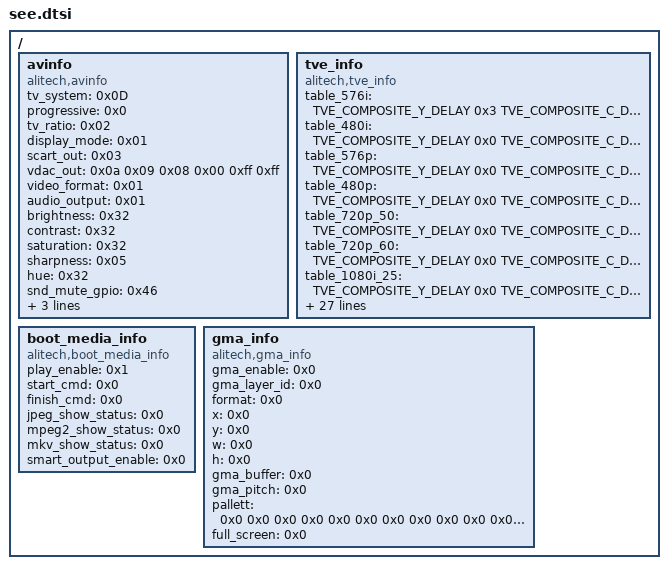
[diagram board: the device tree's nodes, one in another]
/*
 * ALi platform DTS
 * Copyright(C) 2014 ALi Corporation. All rights reserved.
 *
 * This program is free software; you can redistribute it and/or modify
 * it under the terms of the GNU General Public License version 2 as
 * published by the Free Software Foundation.
 *
 * This program is distributed in the hope that it will be useful,
 * but WITHOUT ANY WARRANTY; without even the implied warranty of
 * MERCHANTABILITY or FITNESS FOR A PARTICULAR PURPOSE.  See the
 * GNU General Public License for more details.
 */
 
#include "tve.h"

/{
		#size-cells = <2>;
		avinfo{
			compatible="alitech,avinfo";
			/*eric.cai debug*/
			/* tv_system = /bits/ 8 <0x0D>; */
			tv_system = /bits/ 8 <0x0D>; 
			progressive = /bits/ 8 <0x0>;
			tv_ratio= /bits/ 8 <0x02>;
			display_mode = /bits/ 8 <0x01>;
			scart_out = /bits/ 8 <0x03>;
			vdac_out = /bits/ 8 <0x0a 0x09 0x08 0x00 0xff 0xff>;
			video_format = /bits/ 8 <0x01>;
			audio_output = /bits/ 8 <0x01>;
			brightness = /bits/ 8 <0x32>;
			contrast = /bits/ 8 <0x32>;
			saturation = /bits/ 8 <0x32>;
			sharpness = /bits/ 8 <0x05>;
			hue = /bits/ 8 <0x32>;
			snd_mute_gpio = /bits/ 8 <0x46>;
			snd_mute_polar = /bits/ 8 <0x0>;
			hdcp_disable = /bits/ 8 <0x01>;
			resv = /bits/ 8 <0x00 0x01 0x02 0x03 0x04 0x05 0x06>;
		};
		tve_info{ 
		compatible="alitech,tve_info";
		table_576i = 
	  	< /* field_index  field_value */
			 
				 TVE_COMPOSITE_Y_DELAY              0x3  
				 TVE_COMPOSITE_C_DELAY              0x6  
				 TVE_COMPOSITE_LUMA_LEVEL           0x51  
				 TVE_COMPOSITE_CHRMA_LEVEL          0x67  
				 TVE_COMPOSITE_SYNC_DELAY           0x3  
				 TVE_COMPOSITE_SYNC_LEVEL           0x2  
				 TVE_COMPOSITE_FILTER_C_ENALBE      0x0  
				 TVE_COMPOSITE_FILTER_Y_ENALBE      0x1  
				 TVE_COMPOSITE_PEDESTAL_LEVEL       0x0  
			
				 TVE_COMPONENT_IS_PAL               0x1  
				 TVE_COMPONENT_PAL_MODE             0x0  
				 TVE_COMPONENT_ALL_SMOOTH_ENABLE    0x0  
				 TVE_COMPONENT_BTB_ENALBE           0x0  
				 TVE_COMPONENT_INSERT0_ONOFF        0x1  
				 TVE_COMPONENT_DAC_UPSAMPLEN        0x1  
				 TVE_COMPONENT_Y_DELAY              0x2  
				 TVE_COMPONENT_CB_DELAY             0x2  
				 TVE_COMPONENT_CR_DELAY             0x2  
				 TVE_COMPONENT_LUM_LEVEL            0x52  
				 TVE_COMPONENT_CHRMA_LEVEL          0x50  
				 TVE_COMPONENT_PEDESTAL_LEVEL       0xb  
				 TVE_COMPONENT_UV_SYNC_ONOFF        0x0  
				 TVE_COMPONENT_SYNC_DELAY           0x7  
				 TVE_COMPONENT_SYNC_LEVEL           0x3  
				 TVE_COMPONENT_R_SYNC_ONOFF         0x0  
				 TVE_COMPONENT_G_SYNC_ONOFF         0x0  
				 TVE_COMPONENT_B_SYNC_ONOFF         0x0  
				 TVE_COMPONENT_RGB_R_LEVEL          0x47  
				 TVE_COMPONENT_RGB_G_LEVEL          0x47  
				 TVE_COMPONENT_RGB_B_LEVEL          0x47  
				 TVE_COMPONENT_FILTER_Y_ENALBE      0x1  
				 TVE_COMPONENT_FILTER_C_ENALBE      0x1  
				 TVE_COMPONENT_PEDESTAL_ONOFF       0x0  
				 TVE_COMPONENT_PED_RGB_YPBPR_ENABLE 0x0  
				 TVE_COMPONENT_PED_ADJUST           0x0  
				 TVE_COMPONENT_G2Y                  0x12a  
				 TVE_COMPONENT_G2U                  0x64  
				 TVE_COMPONENT_G2V                  0xd0  
				 TVE_COMPONENT_B2U                  0x205  
				 TVE_COMPONENT_R2V                  0x198  
			
			
				 TVE_BURST_POS_ENABLE               0x1  
				 TVE_BURST_LEVEL_ENABLE             0x1  
				 TVE_BURST_CB_LEVEL                 0x96  
				 TVE_BURST_CR_LEVEL                 0x6a  
				 TVE_BURST_START_POS                0x55  
				 TVE_BURST_END_POS                  0x74  
				 TVE_BURST_SET_FREQ_MODE            0x0  
				 TVE_BURST_FREQ_SIGN                0x0  
				 TVE_BURST_PHASE_COMPENSATION       0x61e8  
				 TVE_BURST_FREQ_RESPONSE            0x0  
			
			
				 TVE_ASYNC_FIFO                     0x4  
				 TVE_CAV_SYNC_HIGH                  0x1  
				 TVE_SYNC_HIGH_WIDTH                0x6  
				 TVE_SYNC_LOW_WIDTH                 0xd  
			
			
				 TVE_VIDEO_DAC_FS                   0x0  
				 TVE_SECAM_PRE_COEFFA3A2            0x0  
				 TVE_SECAM_PRE_COEFFB1A4            0x0  
				 TVE_SECAM_PRE_COEFFB3B2            0x0  
				 TVE_SECAM_F0CB_CENTER              0x0  
				 TVE_SECAM_F0CR_CENTER              0x0  
				 TVE_SECAM_FM_KCBCR_AJUST           0x0  
				 TVE_SECAM_CONTROL                  0x0  
				 TVE_SECAM_NOTCH_COEFB1             0x0  
				 TVE_SECAM_NOTCH_COEFB2B3           0x0  
				 TVE_SECAM_NOTCH_COEFA2A3           0x0  
			
			   //added
			   TVE_COMPONENT_PLUG_OUT_EN          0x1  
				 TVE_COMPONENT_PLUG_DETECT_LINE_CNT_HD 0x4  
				 TVE_CB_CR_INSERT_SW                0x0  //0x84 28bit
				 TVE_VBI_LINE21_EN                  0x0  //0xc8 14bit
			   TVE_COMPONENT_PLUG_DETECT_AMP_ADJUST_HD    0x60  
				 TVE_SCART_PLUG_DETECT_LINE_CNT_HD  0x0        
				 TVE_SCART_PLUG_DETECT_AMP_ADJUST_HD 0x0       
			   TVE_COMPONENT_PLUG_DETECT_FRAME_COUNT 0x1F  
			   TVE_COMPONENT_PLUG_DETECT_VCOUNT 0x2  
			   TVE_COMPONENT_VDAC_ENBUF 0x0  
		>;
		table_480i = 
		< /* field_index  field_value */
		  
				 TVE_COMPOSITE_Y_DELAY              0x0  
				 TVE_COMPOSITE_C_DELAY              0x3  
				 TVE_COMPOSITE_LUMA_LEVEL           0x4c  
				 TVE_COMPOSITE_CHRMA_LEVEL          0x60  
				 TVE_COMPOSITE_SYNC_DELAY           0x0  
				 TVE_COMPOSITE_SYNC_LEVEL           0x5  
				 TVE_COMPOSITE_FILTER_C_ENALBE      0x0  
				 TVE_COMPOSITE_FILTER_Y_ENALBE      0x1  
				 TVE_COMPOSITE_PEDESTAL_LEVEL       0x0  
			
			
				 TVE_COMPONENT_IS_PAL               0x0  
				 TVE_COMPONENT_PAL_MODE             0x0  
				 TVE_COMPONENT_ALL_SMOOTH_ENABLE    0x0  
				 TVE_COMPONENT_BTB_ENALBE           0x1  
				 TVE_COMPONENT_INSERT0_ONOFF        0x1  
				 TVE_COMPONENT_DAC_UPSAMPLEN        0x1  
				 TVE_COMPONENT_Y_DELAY              0x3  
				 TVE_COMPONENT_CB_DELAY             0x1  
				 TVE_COMPONENT_CR_DELAY             0x1  
				 TVE_COMPONENT_LUM_LEVEL            0x4c  
				 TVE_COMPONENT_CHRMA_LEVEL          0x52  
				 TVE_COMPONENT_PEDESTAL_LEVEL       0xb  
				 TVE_COMPONENT_UV_SYNC_ONOFF        0x0  
				 TVE_COMPONENT_SYNC_DELAY           0x7  
				 TVE_COMPONENT_SYNC_LEVEL           0x3  
				 TVE_COMPONENT_R_SYNC_ONOFF         0x0  
				 TVE_COMPONENT_G_SYNC_ONOFF         0x0  
				 TVE_COMPONENT_B_SYNC_ONOFF         0x0  
				 TVE_COMPONENT_RGB_R_LEVEL          0x47  
				 TVE_COMPONENT_RGB_G_LEVEL          0x47  
				 TVE_COMPONENT_RGB_B_LEVEL          0x47  
				 TVE_COMPONENT_FILTER_Y_ENALBE      0x1  
				 TVE_COMPONENT_FILTER_C_ENALBE      0x1  
				 TVE_COMPONENT_PEDESTAL_ONOFF       0x1  
				 TVE_COMPONENT_PED_RGB_YPBPR_ENABLE 0x1  
				 TVE_COMPONENT_PED_ADJUST           0xa8  
				 TVE_COMPONENT_G2Y                  0x12a  
				 TVE_COMPONENT_G2U                  0x64  
				 TVE_COMPONENT_G2V                  0xd0  
				 TVE_COMPONENT_B2U                  0x205  
				 TVE_COMPONENT_R2V                  0x198  
			
			
				 TVE_BURST_POS_ENABLE               0x0  
				 TVE_BURST_LEVEL_ENABLE             0x1  
				 TVE_BURST_CB_LEVEL                 0xd4  
				 TVE_BURST_CR_LEVEL                 0x0  
				 TVE_BURST_START_POS                0x55  
				 TVE_BURST_END_POS                  0x74  
				 TVE_BURST_SET_FREQ_MODE            0x0  
				 TVE_BURST_FREQ_SIGN                0x0  
				 TVE_BURST_PHASE_COMPENSATION       0x3400  
				 TVE_BURST_FREQ_RESPONSE            0x0  
			
			
				 TVE_ASYNC_FIFO                     0x4  
				 TVE_CAV_SYNC_HIGH                  0x1  
				 TVE_SYNC_HIGH_WIDTH                0x6  
				 TVE_SYNC_LOW_WIDTH                 0xd  
			
			
				 TVE_VIDEO_DAC_FS                   0x0  
				 TVE_SECAM_PRE_COEFFA3A2            0x0  
				 TVE_SECAM_PRE_COEFFB1A4            0x0  
				 TVE_SECAM_PRE_COEFFB3B2            0x0  
				 TVE_SECAM_F0CB_CENTER              0x0  
				 TVE_SECAM_F0CR_CENTER              0x0  
				 TVE_SECAM_FM_KCBCR_AJUST           0x0  
				 TVE_SECAM_CONTROL                  0x0  
				 TVE_SECAM_NOTCH_COEFB1             0x0  
				 TVE_SECAM_NOTCH_COEFB2B3           0x0  
				 TVE_SECAM_NOTCH_COEFA2A3           0x0  
				 //added
			   TVE_COMPONENT_PLUG_OUT_EN          0x1  
				 TVE_COMPONENT_PLUG_DETECT_LINE_CNT_HD 0x7  
				 TVE_CB_CR_INSERT_SW                0x1  //0x84 28bit	//C3511 éè3é1￡?S3511 éè3é0
				 TVE_VBI_LINE21_EN                  0x1  //0xc8 14bit
			   TVE_COMPONENT_PLUG_DETECT_AMP_ADJUST_HD                  0x60  
				 TVE_SCART_PLUG_DETECT_LINE_CNT_HD  0x0        
				 TVE_SCART_PLUG_DETECT_AMP_ADJUST_HD 0x0       
			   TVE_COMPONENT_PLUG_DETECT_FRAME_COUNT 0x1F  
			   TVE_COMPONENT_PLUG_DETECT_VCOUNT 0x2  
			   TVE_COMPONENT_VDAC_ENBUF 0x0  

		>;
		table_576p = 
		< /* field_index  field_value */
	 
				 TVE_COMPOSITE_Y_DELAY              0x0  
				 TVE_COMPOSITE_C_DELAY              0x2  
				 TVE_COMPOSITE_LUMA_LEVEL           0x50  
				 TVE_COMPOSITE_CHRMA_LEVEL          0x68  
				 TVE_COMPOSITE_SYNC_DELAY           0x0  
				 TVE_COMPOSITE_SYNC_LEVEL           0x4  
				 TVE_COMPOSITE_FILTER_C_ENALBE      0x0  
				 TVE_COMPOSITE_FILTER_Y_ENALBE      0x1  
				 TVE_COMPOSITE_PEDESTAL_LEVEL       0x0  

				 TVE_COMPONENT_IS_PAL               0x0  
				 TVE_COMPONENT_PAL_MODE             0x0  
				 TVE_COMPONENT_ALL_SMOOTH_ENABLE    0x0  
				 TVE_COMPONENT_BTB_ENALBE           0x0  
				 TVE_COMPONENT_INSERT0_ONOFF        0x1  
				 TVE_COMPONENT_DAC_UPSAMPLEN        0x1  
				 TVE_COMPONENT_Y_DELAY              0x1  
				 TVE_COMPONENT_CB_DELAY             0x1  
				 TVE_COMPONENT_CR_DELAY             0x1  
				 TVE_COMPONENT_LUM_LEVEL            0x52  
				 TVE_COMPONENT_CHRMA_LEVEL          0x52  
				 TVE_COMPONENT_PEDESTAL_LEVEL       0xa  
				 TVE_COMPONENT_UV_SYNC_ONOFF        0x0  
				 TVE_COMPONENT_SYNC_DELAY           0x7  
				 TVE_COMPONENT_SYNC_LEVEL           0x3  
				 TVE_COMPONENT_R_SYNC_ONOFF         0x0  
				 TVE_COMPONENT_G_SYNC_ONOFF         0x0  
				 TVE_COMPONENT_B_SYNC_ONOFF         0x0  
				 TVE_COMPONENT_RGB_R_LEVEL          0x49  
				 TVE_COMPONENT_RGB_G_LEVEL          0x49  
				 TVE_COMPONENT_RGB_B_LEVEL          0x49  
				 TVE_COMPONENT_FILTER_Y_ENALBE      0x1  
				 TVE_COMPONENT_FILTER_C_ENALBE      0x1  
				 TVE_COMPONENT_PEDESTAL_ONOFF       0x0  
				 TVE_COMPONENT_PED_RGB_YPBPR_ENABLE 0x0  
				 TVE_COMPONENT_PED_ADJUST           0x0  
				 TVE_COMPONENT_G2Y                  0x12a  
				 TVE_COMPONENT_G2U                  0x64  
				 TVE_COMPONENT_G2V                  0xd0  
				 TVE_COMPONENT_B2U                  0x205  
				 TVE_COMPONENT_R2V                  0x198  

				 TVE_BURST_POS_ENABLE               0x0  
				 TVE_BURST_LEVEL_ENABLE             0x0  
				 TVE_BURST_CB_LEVEL                 0xd4  
				 TVE_BURST_CR_LEVEL                 0x0  
				 TVE_BURST_START_POS                0x0  
				 TVE_BURST_END_POS                  0x0  
				 TVE_BURST_SET_FREQ_MODE            0x0  
				 TVE_BURST_FREQ_SIGN                0x0  
				 TVE_BURST_PHASE_COMPENSATION       0x0  
				 TVE_BURST_FREQ_RESPONSE            0x0  

				 TVE_ASYNC_FIFO                     0x4  
				 TVE_CAV_SYNC_HIGH                  0x1  
				 TVE_SYNC_HIGH_WIDTH                0x6  
				 TVE_SYNC_LOW_WIDTH                 0xd  

				 TVE_VIDEO_DAC_FS                   0x0  
				 TVE_SECAM_PRE_COEFFA3A2            0x0  
				 TVE_SECAM_PRE_COEFFB1A4            0x0  
				 TVE_SECAM_PRE_COEFFB3B2            0x0  
				 TVE_SECAM_F0CB_CENTER              0x0  
				 TVE_SECAM_F0CR_CENTER              0x0  
				 TVE_SECAM_FM_KCBCR_AJUST           0x0  
				 TVE_SECAM_CONTROL                  0x0  
				 TVE_SECAM_NOTCH_COEFB1             0x0  
				 TVE_SECAM_NOTCH_COEFB2B3           0x0  
				 TVE_SECAM_NOTCH_COEFA2A3           0x0  
				 TVE_COMPONENT_PLUG_OUT_EN          0x1        
				 TVE_COMPONENT_PLUG_DETECT_LINE_CNT_HD 0xe     
				 TVE_CB_CR_INSERT_SW                0x0        
				 TVE_VBI_LINE21_EN                  0x0        
				 TVE_COMPONENT_PLUG_DETECT_AMP_ADJUST_HD 0x60  
				 TVE_SCART_PLUG_DETECT_LINE_CNT_HD  0x0        
				 TVE_SCART_PLUG_DETECT_AMP_ADJUST_HD 0x0       
				 TVE_COMPONENT_PLUG_DETECT_FRAME_COUNT 0x1F     
				 TVE_COMPONENT_PLUG_DETECT_VCOUNT 0x2          
				 TVE_COMPONENT_VDAC_ENBUF 0x0                  
   >;
	 table_480p = 
	 </* field_index  field_value */ 
				  
				 TVE_COMPOSITE_Y_DELAY              0x0  
				 TVE_COMPOSITE_C_DELAY              0x2  
				 TVE_COMPOSITE_LUMA_LEVEL           0x50  
				 TVE_COMPOSITE_CHRMA_LEVEL          0x68  
				 TVE_COMPOSITE_SYNC_DELAY           0x0  
				 TVE_COMPOSITE_SYNC_LEVEL           0x4  
				 TVE_COMPOSITE_FILTER_C_ENALBE      0x0  
				 TVE_COMPOSITE_FILTER_Y_ENALBE      0x1  
				 TVE_COMPOSITE_PEDESTAL_LEVEL       0x0  
			
			
				 TVE_COMPONENT_IS_PAL               0x0  
				 TVE_COMPONENT_PAL_MODE             0x0  
				 TVE_COMPONENT_ALL_SMOOTH_ENABLE    0x0  
				 TVE_COMPONENT_BTB_ENALBE           0x0  
				 TVE_COMPONENT_INSERT0_ONOFF        0x1  
				 TVE_COMPONENT_DAC_UPSAMPLEN        0x1  
				 TVE_COMPONENT_Y_DELAY              0x1  
				 TVE_COMPONENT_CB_DELAY             0x1  
				 TVE_COMPONENT_CR_DELAY             0x1  
				 TVE_COMPONENT_LUM_LEVEL            0x52  
				 TVE_COMPONENT_CHRMA_LEVEL          0x52  
				 TVE_COMPONENT_PEDESTAL_LEVEL       0xa  
				 TVE_COMPONENT_UV_SYNC_ONOFF        0x0  
				 TVE_COMPONENT_SYNC_DELAY           0x7  
				 TVE_COMPONENT_SYNC_LEVEL           0x3  
				 TVE_COMPONENT_R_SYNC_ONOFF         0x0  
				 TVE_COMPONENT_G_SYNC_ONOFF         0x0  
				 TVE_COMPONENT_B_SYNC_ONOFF         0x0  
				 TVE_COMPONENT_RGB_R_LEVEL          0x49  
				 TVE_COMPONENT_RGB_G_LEVEL          0x49  
				 TVE_COMPONENT_RGB_B_LEVEL          0x49  
				 TVE_COMPONENT_FILTER_Y_ENALBE      0x1  
				 TVE_COMPONENT_FILTER_C_ENALBE      0x1  
				 TVE_COMPONENT_PEDESTAL_ONOFF       0x0  
				 TVE_COMPONENT_PED_RGB_YPBPR_ENABLE 0x0  
				 TVE_COMPONENT_PED_ADJUST           0x0  
				 TVE_COMPONENT_G2Y                  0x12a  
				 TVE_COMPONENT_G2U                  0x64  
				 TVE_COMPONENT_G2V                  0xd0  
				 TVE_COMPONENT_B2U                  0x205  
				 TVE_COMPONENT_R2V                  0x198  
			
			
				 TVE_BURST_POS_ENABLE               0x0  
				 TVE_BURST_LEVEL_ENABLE             0x0  
				 TVE_BURST_CB_LEVEL                 0xd4  
				 TVE_BURST_CR_LEVEL                 0x0  
				 TVE_BURST_START_POS                0x0  
				 TVE_BURST_END_POS                  0x0  
				 TVE_BURST_SET_FREQ_MODE            0x0  
				 TVE_BURST_FREQ_SIGN                0x0  
				 TVE_BURST_PHASE_COMPENSATION       0x0  
				 TVE_BURST_FREQ_RESPONSE            0x0  
			
			
				 TVE_ASYNC_FIFO                     0x4  
				 TVE_CAV_SYNC_HIGH                  0x1  
				 TVE_SYNC_HIGH_WIDTH                0x6  
				 TVE_SYNC_LOW_WIDTH                 0xd  
			
			
				 TVE_VIDEO_DAC_FS                   0x0  
				 TVE_SECAM_PRE_COEFFA3A2            0x0  
				 TVE_SECAM_PRE_COEFFB1A4            0x0  
				 TVE_SECAM_PRE_COEFFB3B2            0x0  
				 TVE_SECAM_F0CB_CENTER              0x0  
				 TVE_SECAM_F0CR_CENTER              0x0  
				 TVE_SECAM_FM_KCBCR_AJUST           0x0  
				 TVE_SECAM_CONTROL                  0x0  
				 TVE_SECAM_NOTCH_COEFB1             0x0  
				 TVE_SECAM_NOTCH_COEFB2B3           0x0  
				 TVE_SECAM_NOTCH_COEFA2A3           0x0  
			   //added
			   TVE_COMPONENT_PLUG_OUT_EN          0x1  
				 TVE_COMPONENT_PLUG_DETECT_LINE_CNT_HD 0xe     
				 TVE_CB_CR_INSERT_SW                0x0  //0x84 28bit
				 TVE_VBI_LINE21_EN                  0x0  //0xc8 14bit
			   TVE_COMPONENT_PLUG_DETECT_AMP_ADJUST_HD    0x60  
			   TVE_SCART_PLUG_DETECT_LINE_CNT_HD  0x0  
				 TVE_SCART_PLUG_DETECT_AMP_ADJUST_HD 0x0       

			   TVE_COMPONENT_PLUG_DETECT_FRAME_COUNT 0x1F  
			   TVE_COMPONENT_PLUG_DETECT_VCOUNT 0x2  
			   TVE_COMPONENT_VDAC_ENBUF 0x0  
			>;
			table_720p_50 = 
			</* field_index  field_value */
				  
			 TVE_COMPOSITE_Y_DELAY              0x0  
			 TVE_COMPOSITE_C_DELAY              0x2  
			 TVE_COMPOSITE_LUMA_LEVEL           0x50  
			 TVE_COMPOSITE_CHRMA_LEVEL          0x68  
			 TVE_COMPOSITE_SYNC_DELAY           0x0  
			 TVE_COMPOSITE_SYNC_LEVEL           0x4  
			 TVE_COMPOSITE_FILTER_C_ENALBE      0x0  
			 TVE_COMPOSITE_FILTER_Y_ENALBE      0x1  
			 TVE_COMPOSITE_PEDESTAL_LEVEL       0x0  

			 TVE_COMPONENT_IS_PAL               0x0  
			 TVE_COMPONENT_PAL_MODE             0x0  
			 TVE_COMPONENT_ALL_SMOOTH_ENABLE    0x0  
			 TVE_COMPONENT_BTB_ENALBE           0x0  
			 TVE_COMPONENT_INSERT0_ONOFF        0x1  
			 TVE_COMPONENT_DAC_UPSAMPLEN        0x1  
			 TVE_COMPONENT_Y_DELAY              0x6  
			 TVE_COMPONENT_CB_DELAY             0x5  
			 TVE_COMPONENT_CR_DELAY             0x5  
			 TVE_COMPONENT_LUM_LEVEL            0x52  
			 TVE_COMPONENT_CHRMA_LEVEL          0x52  
			 TVE_COMPONENT_PEDESTAL_LEVEL       0x0  
			 TVE_COMPONENT_UV_SYNC_ONOFF        0x0  
			 TVE_COMPONENT_SYNC_DELAY           0x0  
			 TVE_COMPONENT_SYNC_LEVEL           0x3  
			 TVE_COMPONENT_R_SYNC_ONOFF         0x0  
			 TVE_COMPONENT_G_SYNC_ONOFF         0x0  
			 TVE_COMPONENT_B_SYNC_ONOFF         0x0  
			 TVE_COMPONENT_RGB_R_LEVEL          0x49  
			 TVE_COMPONENT_RGB_G_LEVEL          0x49  
			 TVE_COMPONENT_RGB_B_LEVEL          0x49  
			 TVE_COMPONENT_FILTER_Y_ENALBE      0x1  
			 TVE_COMPONENT_FILTER_C_ENALBE      0x1  
			 TVE_COMPONENT_PEDESTAL_ONOFF       0x0  
			 TVE_COMPONENT_PED_RGB_YPBPR_ENABLE 0x0  
			 TVE_COMPONENT_PED_ADJUST           0x0  
			 TVE_COMPONENT_G2Y                  0x12a  
			 TVE_COMPONENT_G2U                  0x64  
			 TVE_COMPONENT_G2V                  0xd0  
			 TVE_COMPONENT_B2U                  0x21d  
			 TVE_COMPONENT_R2V                  0x1cb  

			 TVE_BURST_POS_ENABLE               0x0  
			 TVE_BURST_LEVEL_ENABLE             0x0  
			 TVE_BURST_CB_LEVEL                 0xd4  
			 TVE_BURST_CR_LEVEL                 0x0  
			 TVE_BURST_START_POS                0x0  
			 TVE_BURST_END_POS                  0x0  
			 TVE_BURST_SET_FREQ_MODE            0x0  
			 TVE_BURST_FREQ_SIGN                0x0  
			 TVE_BURST_PHASE_COMPENSATION       0x0  
			 TVE_BURST_FREQ_RESPONSE            0x0  

			 TVE_ASYNC_FIFO                     0x4  
			 TVE_CAV_SYNC_HIGH                  0x1  
			 TVE_SYNC_HIGH_WIDTH                0x6  
			 TVE_SYNC_LOW_WIDTH                 0xd  

			 TVE_VIDEO_DAC_FS                   0x0  
			 TVE_SECAM_PRE_COEFFA3A2            0x0  
			 TVE_SECAM_PRE_COEFFB1A4            0x0  
			 TVE_SECAM_PRE_COEFFB3B2            0x0  
			 TVE_SECAM_F0CB_CENTER              0x0  
			 TVE_SECAM_F0CR_CENTER              0x0  
			 TVE_SECAM_FM_KCBCR_AJUST           0x0  
			 TVE_SECAM_CONTROL                  0x0  
			 TVE_SECAM_NOTCH_COEFB1             0x0  
			 TVE_SECAM_NOTCH_COEFB2B3           0x0  
			 TVE_SECAM_NOTCH_COEFA2A3           0x0  
			 TVE_COMPONENT_PLUG_OUT_EN          0x1        
			 TVE_COMPONENT_PLUG_DETECT_LINE_CNT_HD 0x6     
			 TVE_CB_CR_INSERT_SW                0x0        
			 TVE_VBI_LINE21_EN                  0x0        
			 TVE_COMPONENT_PLUG_DETECT_AMP_ADJUST_HD 0x60  
			 TVE_SCART_PLUG_DETECT_LINE_CNT_HD  0x0        
			 TVE_SCART_PLUG_DETECT_AMP_ADJUST_HD 0x0       
			 TVE_COMPONENT_PLUG_DETECT_FRAME_COUNT 0x1F     
			 TVE_COMPONENT_PLUG_DETECT_VCOUNT 0x2          
			 TVE_COMPONENT_VDAC_ENBUF 0x0                  

				>;
		table_720p_60 = 
		</* field_index  field_value */					 
			 
			 TVE_COMPOSITE_Y_DELAY              0x0  
			 TVE_COMPOSITE_C_DELAY              0x2  
			 TVE_COMPOSITE_LUMA_LEVEL           0x50  
			 TVE_COMPOSITE_CHRMA_LEVEL          0x68  
			 TVE_COMPOSITE_SYNC_DELAY           0x0  
			 TVE_COMPOSITE_SYNC_LEVEL           0x4  
			 TVE_COMPOSITE_FILTER_C_ENALBE      0x0  
			 TVE_COMPOSITE_FILTER_Y_ENALBE      0x1  
			 TVE_COMPOSITE_PEDESTAL_LEVEL       0x0  
		
		
			 TVE_COMPONENT_IS_PAL               0x0  
			 TVE_COMPONENT_PAL_MODE             0x0  
			 TVE_COMPONENT_ALL_SMOOTH_ENABLE    0x0  
			 TVE_COMPONENT_BTB_ENALBE           0x0  
			 TVE_COMPONENT_INSERT0_ONOFF        0x1  
			 TVE_COMPONENT_DAC_UPSAMPLEN        0x1  
			 TVE_COMPONENT_Y_DELAY              0x7  
			 TVE_COMPONENT_CB_DELAY             0x6  
			 TVE_COMPONENT_CR_DELAY             0x6  
			 TVE_COMPONENT_LUM_LEVEL            0x52  
			 TVE_COMPONENT_CHRMA_LEVEL          0x52  
			 TVE_COMPONENT_PEDESTAL_LEVEL       0x0  
			 TVE_COMPONENT_UV_SYNC_ONOFF        0x0  
			 TVE_COMPONENT_SYNC_DELAY           0x5  
			 TVE_COMPONENT_SYNC_LEVEL           0x3  
			 TVE_COMPONENT_R_SYNC_ONOFF         0x0  
			 TVE_COMPONENT_G_SYNC_ONOFF         0x0  
			 TVE_COMPONENT_B_SYNC_ONOFF         0x0  
			 TVE_COMPONENT_RGB_R_LEVEL          0x49  
			 TVE_COMPONENT_RGB_G_LEVEL          0x49  
			 TVE_COMPONENT_RGB_B_LEVEL          0x49  
			 TVE_COMPONENT_FILTER_Y_ENALBE      0x1  
			 TVE_COMPONENT_FILTER_C_ENALBE      0x1  
			 TVE_COMPONENT_PEDESTAL_ONOFF       0x0  
			 TVE_COMPONENT_PED_RGB_YPBPR_ENABLE 0x0  
			 TVE_COMPONENT_PED_ADJUST           0x0  
			 TVE_COMPONENT_G2Y                  0x12a  
			 TVE_COMPONENT_G2U                  0x64  
			 TVE_COMPONENT_G2V                  0xd0  
			 TVE_COMPONENT_B2U                  0x21d  
			 TVE_COMPONENT_R2V                  0x1cb  
		
		
			 TVE_BURST_POS_ENABLE               0x0  
			 TVE_BURST_LEVEL_ENABLE             0x0  
			 TVE_BURST_CB_LEVEL                 0xd4  
			 TVE_BURST_CR_LEVEL                 0x0  
			 TVE_BURST_START_POS                0x0  
			 TVE_BURST_END_POS                  0x0  
			 TVE_BURST_SET_FREQ_MODE            0x0  
			 TVE_BURST_FREQ_SIGN                0x0  
			 TVE_BURST_PHASE_COMPENSATION       0x0  
			 TVE_BURST_FREQ_RESPONSE            0x0  
		
		
			 TVE_ASYNC_FIFO                     0x4  
			 TVE_CAV_SYNC_HIGH                  0x1  
			 TVE_SYNC_HIGH_WIDTH                0x6  
			 TVE_SYNC_LOW_WIDTH                 0xf  
		
		
			 TVE_VIDEO_DAC_FS                   0x0  
			 TVE_SECAM_PRE_COEFFA3A2            0x0  
			 TVE_SECAM_PRE_COEFFB1A4            0x0  
			 TVE_SECAM_PRE_COEFFB3B2            0x0  
			 TVE_SECAM_F0CB_CENTER              0x0  
			 TVE_SECAM_F0CR_CENTER              0x0  
			 TVE_SECAM_FM_KCBCR_AJUST           0x0  
			 TVE_SECAM_CONTROL                  0x0  
			 TVE_SECAM_NOTCH_COEFB1             0x0  
			 TVE_SECAM_NOTCH_COEFB2B3           0x0  
			 TVE_SECAM_NOTCH_COEFA2A3           0x0  
			 TVE_COMPONENT_PLUG_OUT_EN          0x1        
			 TVE_COMPONENT_PLUG_DETECT_LINE_CNT_HD 0x6     
			 TVE_CB_CR_INSERT_SW                0x0        
			 TVE_VBI_LINE21_EN                  0x0        
			 TVE_COMPONENT_PLUG_DETECT_AMP_ADJUST_HD 0x60  
			 TVE_SCART_PLUG_DETECT_LINE_CNT_HD  0x0        
			 TVE_SCART_PLUG_DETECT_AMP_ADJUST_HD 0x0       
			 TVE_COMPONENT_PLUG_DETECT_FRAME_COUNT 0x1F     
			 TVE_COMPONENT_PLUG_DETECT_VCOUNT 0x2          
			 TVE_COMPONENT_VDAC_ENBUF 0x0                  
			
		 >;

		table_1080i_25 = 
		< /* field_index  field_value */
	 
				 TVE_COMPOSITE_Y_DELAY              0x0  
				 TVE_COMPOSITE_C_DELAY              0x2  
				 TVE_COMPOSITE_LUMA_LEVEL           0x50  
				 TVE_COMPOSITE_CHRMA_LEVEL          0x68  
				 TVE_COMPOSITE_SYNC_DELAY           0x0  
				 TVE_COMPOSITE_SYNC_LEVEL           0x4  
				 TVE_COMPOSITE_FILTER_C_ENALBE      0x0  
				 TVE_COMPOSITE_FILTER_Y_ENALBE      0x1  
				 TVE_COMPOSITE_PEDESTAL_LEVEL       0x0  
			
			
				 TVE_COMPONENT_IS_PAL               0x0  
				 TVE_COMPONENT_PAL_MODE             0x0  
				 TVE_COMPONENT_ALL_SMOOTH_ENABLE    0x0  
				 TVE_COMPONENT_BTB_ENALBE           0x0  
				 TVE_COMPONENT_INSERT0_ONOFF        0x1  
				 TVE_COMPONENT_DAC_UPSAMPLEN        0x1  
				 TVE_COMPONENT_Y_DELAY              0x6  
				 TVE_COMPONENT_CB_DELAY             0x5  
				 TVE_COMPONENT_CR_DELAY             0x5  
				 TVE_COMPONENT_LUM_LEVEL            0x52  
				 TVE_COMPONENT_CHRMA_LEVEL          0x52  
				 TVE_COMPONENT_PEDESTAL_LEVEL       0x0  
				 TVE_COMPONENT_UV_SYNC_ONOFF        0x0  
				 TVE_COMPONENT_SYNC_DELAY           0x5  
				 TVE_COMPONENT_SYNC_LEVEL           0x3  
				 TVE_COMPONENT_R_SYNC_ONOFF         0x0  
				 TVE_COMPONENT_G_SYNC_ONOFF         0x0  
				 TVE_COMPONENT_B_SYNC_ONOFF         0x0  
				 TVE_COMPONENT_RGB_R_LEVEL          0x49  
				 TVE_COMPONENT_RGB_G_LEVEL          0x49  
				 TVE_COMPONENT_RGB_B_LEVEL          0x49  
				 TVE_COMPONENT_FILTER_Y_ENALBE      0x1  
				 TVE_COMPONENT_FILTER_C_ENALBE      0x1  
				 TVE_COMPONENT_PEDESTAL_ONOFF       0x0  
				 TVE_COMPONENT_PED_RGB_YPBPR_ENABLE 0x0  
				 TVE_COMPONENT_PED_ADJUST           0x0  
				 TVE_COMPONENT_G2Y                  0x12a  
				 TVE_COMPONENT_G2U                  0x64  
				 TVE_COMPONENT_G2V                  0xd0  
				 TVE_COMPONENT_B2U                  0x21d  
				 TVE_COMPONENT_R2V                  0x1cb  
			
			
				 TVE_BURST_POS_ENABLE               0x0  
				 TVE_BURST_LEVEL_ENABLE             0x0  
				 TVE_BURST_CB_LEVEL                 0xd4  
				 TVE_BURST_CR_LEVEL                 0x0  
				 TVE_BURST_START_POS                0x0  
				 TVE_BURST_END_POS                  0x0  
				 TVE_BURST_SET_FREQ_MODE            0x0  
				 TVE_BURST_FREQ_SIGN                0x0  
				 TVE_BURST_PHASE_COMPENSATION       0x0  
				 TVE_BURST_FREQ_RESPONSE            0x0  
			
			
				 TVE_ASYNC_FIFO                     0x4  
				 TVE_CAV_SYNC_HIGH                  0x1  
				 TVE_SYNC_HIGH_WIDTH                0x6  
				 TVE_SYNC_LOW_WIDTH                 0xd  
			
			
				 TVE_VIDEO_DAC_FS                   0x0  
				 TVE_SECAM_PRE_COEFFA3A2            0x0  
				 TVE_SECAM_PRE_COEFFB1A4            0x0  
				 TVE_SECAM_PRE_COEFFB3B2            0x0  
				 TVE_SECAM_F0CB_CENTER              0x0  
				 TVE_SECAM_F0CR_CENTER              0x0  
				 TVE_SECAM_FM_KCBCR_AJUST           0x0  
				 TVE_SECAM_CONTROL                  0x0  
				 TVE_SECAM_NOTCH_COEFB1             0x0  
				 TVE_SECAM_NOTCH_COEFB2B3           0x0  
				 TVE_SECAM_NOTCH_COEFA2A3           0x0  
		     //added
		     TVE_COMPONENT_PLUG_OUT_EN          0x1  
				 TVE_COMPONENT_PLUG_DETECT_LINE_CNT_HD 0x6     
				 TVE_CB_CR_INSERT_SW                0x0  //0x84 28bit
				 TVE_VBI_LINE21_EN                  0x0  //0xc8 14bit
		     TVE_COMPONENT_PLUG_DETECT_AMP_ADJUST_HD                  0x60  
		     TVE_SCART_PLUG_DETECT_LINE_CNT_HD  0x0  
				 TVE_SCART_PLUG_DETECT_AMP_ADJUST_HD 0x0       
			
			
		     TVE_COMPONENT_PLUG_DETECT_FRAME_COUNT 0x1F  
		     TVE_COMPONENT_PLUG_DETECT_VCOUNT 0x2  
		     TVE_COMPONENT_VDAC_ENBUF 0x0  
	 >;

	table_1080i_30 = 
	< /* field_index  field_value */
		 
				 TVE_COMPOSITE_Y_DELAY              0x0  
				 TVE_COMPOSITE_C_DELAY              0x2  
				 TVE_COMPOSITE_LUMA_LEVEL           0x50  
				 TVE_COMPOSITE_CHRMA_LEVEL          0x68  
				 TVE_COMPOSITE_SYNC_DELAY           0x0  
				 TVE_COMPOSITE_SYNC_LEVEL           0x4  
				 TVE_COMPOSITE_FILTER_C_ENALBE      0x0  
				 TVE_COMPOSITE_FILTER_Y_ENALBE      0x1  
				 TVE_COMPOSITE_PEDESTAL_LEVEL       0x0  
			
			
				 TVE_COMPONENT_IS_PAL               0x0  
				 TVE_COMPONENT_PAL_MODE             0x0  
				 TVE_COMPONENT_ALL_SMOOTH_ENABLE    0x0  
				 TVE_COMPONENT_BTB_ENALBE           0x0  
				 TVE_COMPONENT_INSERT0_ONOFF        0x1  
				 TVE_COMPONENT_DAC_UPSAMPLEN        0x1  
				 TVE_COMPONENT_Y_DELAY              0x6  
				 TVE_COMPONENT_CB_DELAY             0x5  
				 TVE_COMPONENT_CR_DELAY             0x5  
				 TVE_COMPONENT_LUM_LEVEL            0x52  
				 TVE_COMPONENT_CHRMA_LEVEL          0x51  
				 TVE_COMPONENT_PEDESTAL_LEVEL       0x0  
				 TVE_COMPONENT_UV_SYNC_ONOFF        0x0  
				 TVE_COMPONENT_SYNC_DELAY           0x5  
				 TVE_COMPONENT_SYNC_LEVEL           0x3  
				 TVE_COMPONENT_R_SYNC_ONOFF         0x0  
				 TVE_COMPONENT_G_SYNC_ONOFF         0x0  
				 TVE_COMPONENT_B_SYNC_ONOFF         0x0  
				 TVE_COMPONENT_RGB_R_LEVEL          0x49  
				 TVE_COMPONENT_RGB_G_LEVEL          0x49  
				 TVE_COMPONENT_RGB_B_LEVEL          0x49  
				 TVE_COMPONENT_FILTER_Y_ENALBE      0x1  
				 TVE_COMPONENT_FILTER_C_ENALBE      0x1  
				 TVE_COMPONENT_PEDESTAL_ONOFF       0x0  
				 TVE_COMPONENT_PED_RGB_YPBPR_ENABLE 0x0  
				 TVE_COMPONENT_PED_ADJUST           0x0  
				 TVE_COMPONENT_G2Y                  0x12a  
				 TVE_COMPONENT_G2U                  0x64  
				 TVE_COMPONENT_G2V                  0xd0  
				 TVE_COMPONENT_B2U                  0x21d  
				 TVE_COMPONENT_R2V                  0x1cb  

				 TVE_BURST_POS_ENABLE               0x0  
				 TVE_BURST_LEVEL_ENABLE             0x0  
				 TVE_BURST_CB_LEVEL                 0xd4  
				 TVE_BURST_CR_LEVEL                 0x0  
				 TVE_BURST_START_POS                0x0  
				 TVE_BURST_END_POS                  0x0  
				 TVE_BURST_SET_FREQ_MODE            0x0  
				 TVE_BURST_FREQ_SIGN                0x0  
				 TVE_BURST_PHASE_COMPENSATION       0x0  
				 TVE_BURST_FREQ_RESPONSE            0x0  

				 TVE_ASYNC_FIFO                     0x4  
				 TVE_CAV_SYNC_HIGH                  0x1  
				 TVE_SYNC_HIGH_WIDTH                0x6  
				 TVE_SYNC_LOW_WIDTH                 0xd  

				 TVE_VIDEO_DAC_FS                   0x0  
				 TVE_SECAM_PRE_COEFFA3A2            0x0  
				 TVE_SECAM_PRE_COEFFB1A4            0x0  
				 TVE_SECAM_PRE_COEFFB3B2            0x0  
				 TVE_SECAM_F0CB_CENTER              0x0  
				 TVE_SECAM_F0CR_CENTER              0x0  
				 TVE_SECAM_FM_KCBCR_AJUST           0x0  
				 TVE_SECAM_CONTROL                  0x0  
				 TVE_SECAM_NOTCH_COEFB1             0x0  
				 TVE_SECAM_NOTCH_COEFB2B3           0x0  
				 TVE_SECAM_NOTCH_COEFA2A3           0x0  
		     //added
		     TVE_COMPONENT_PLUG_OUT_EN          0x1  
				 TVE_COMPONENT_PLUG_DETECT_LINE_CNT_HD 0x6     
				 TVE_CB_CR_INSERT_SW                0x0  //0x84 28bit
				 TVE_VBI_LINE21_EN                  0x0  //0xc8 14bit
		     TVE_COMPONENT_PLUG_DETECT_AMP_ADJUST_HD                  0x60  
		     TVE_SCART_PLUG_DETECT_LINE_CNT_HD  0x0  
				 TVE_SCART_PLUG_DETECT_AMP_ADJUST_HD 0x0       

		     TVE_COMPONENT_PLUG_DETECT_FRAME_COUNT 0x1F  
		     TVE_COMPONENT_PLUG_DETECT_VCOUNT 0x2  
		     TVE_COMPONENT_VDAC_ENBUF 0x0  

		>;								 
								 
		table_1080p_24 = 
	 	< /* field_index  field_value */
			 
				 TVE_COMPOSITE_Y_DELAY              0x0  
				 TVE_COMPOSITE_C_DELAY              0x2  
				 TVE_COMPOSITE_LUMA_LEVEL           0x50  
				 TVE_COMPOSITE_CHRMA_LEVEL          0x68  
				 TVE_COMPOSITE_SYNC_DELAY           0x0  
				 TVE_COMPOSITE_SYNC_LEVEL           0x4  
				 TVE_COMPOSITE_FILTER_C_ENALBE      0x0  
				 TVE_COMPOSITE_FILTER_Y_ENALBE      0x1  
				 TVE_COMPOSITE_PEDESTAL_LEVEL       0x0  
			
			
				 TVE_COMPONENT_IS_PAL               0x0  
				 TVE_COMPONENT_PAL_MODE             0x0  
				 TVE_COMPONENT_ALL_SMOOTH_ENABLE    0x0  
				 TVE_COMPONENT_BTB_ENALBE           0x0  
				 TVE_COMPONENT_INSERT0_ONOFF        0x1  
				 TVE_COMPONENT_DAC_UPSAMPLEN        0x1  
				 TVE_COMPONENT_Y_DELAY              0x6  
				 TVE_COMPONENT_CB_DELAY             0x5  
				 TVE_COMPONENT_CR_DELAY             0x5  
				 TVE_COMPONENT_LUM_LEVEL            0x52  
				 TVE_COMPONENT_CHRMA_LEVEL          0x52  
				 TVE_COMPONENT_PEDESTAL_LEVEL       0x0  
				 TVE_COMPONENT_UV_SYNC_ONOFF        0x0  
				 TVE_COMPONENT_SYNC_DELAY           0x5  
				 TVE_COMPONENT_SYNC_LEVEL           0x3  
				 TVE_COMPONENT_R_SYNC_ONOFF         0x0  
				 TVE_COMPONENT_G_SYNC_ONOFF         0x0  
				 TVE_COMPONENT_B_SYNC_ONOFF         0x0  
				 TVE_COMPONENT_RGB_R_LEVEL          0x49  
				 TVE_COMPONENT_RGB_G_LEVEL          0x49  
				 TVE_COMPONENT_RGB_B_LEVEL          0x49  
				 TVE_COMPONENT_FILTER_Y_ENALBE      0x1  
				 TVE_COMPONENT_FILTER_C_ENALBE      0x1  
				 TVE_COMPONENT_PEDESTAL_ONOFF       0x0  
				 TVE_COMPONENT_PED_RGB_YPBPR_ENABLE 0x0  
				 TVE_COMPONENT_PED_ADJUST           0x0  
				 TVE_COMPONENT_G2Y                  0x12a  
				 TVE_COMPONENT_G2U                  0x64  
				 TVE_COMPONENT_G2V                  0xd0  
				 TVE_COMPONENT_B2U                  0x21d  
				 TVE_COMPONENT_R2V                  0x1cb  
			
			
				 TVE_BURST_POS_ENABLE               0x0  
				 TVE_BURST_LEVEL_ENABLE             0x0  
				 TVE_BURST_CB_LEVEL                 0xd4  
				 TVE_BURST_CR_LEVEL                 0x0  
				 TVE_BURST_START_POS                0x0  
				 TVE_BURST_END_POS                  0x0  
				 TVE_BURST_SET_FREQ_MODE            0x0  
				 TVE_BURST_FREQ_SIGN                0x0  
				 TVE_BURST_PHASE_COMPENSATION       0x0  
				 TVE_BURST_FREQ_RESPONSE            0x0  
			
			
				 TVE_ASYNC_FIFO                     0x4  
				 TVE_CAV_SYNC_HIGH                  0x1  
				 TVE_SYNC_HIGH_WIDTH                0x6  
				 TVE_SYNC_LOW_WIDTH                 0xd  
			
			
				 TVE_VIDEO_DAC_FS                   0x0  
				 TVE_SECAM_PRE_COEFFA3A2            0x0  
				 TVE_SECAM_PRE_COEFFB1A4            0x0  
				 TVE_SECAM_PRE_COEFFB3B2            0x0  
				 TVE_SECAM_F0CB_CENTER              0x0  
				 TVE_SECAM_F0CR_CENTER              0x0  
				 TVE_SECAM_FM_KCBCR_AJUST           0x0  
				 TVE_SECAM_CONTROL                  0x0  
				 TVE_SECAM_NOTCH_COEFB1             0x0  
				 TVE_SECAM_NOTCH_COEFB2B3           0x0  
				 TVE_SECAM_NOTCH_COEFA2A3           0x0  
				 TVE_COMPONENT_PLUG_OUT_EN          0x1        
				 TVE_COMPONENT_PLUG_DETECT_LINE_CNT_HD 0x6     
				 TVE_CB_CR_INSERT_SW                0x0        
				 TVE_VBI_LINE21_EN                  0x0        
				 TVE_COMPONENT_PLUG_DETECT_AMP_ADJUST_HD 0x60  
				 TVE_SCART_PLUG_DETECT_LINE_CNT_HD  0x0        
				 TVE_SCART_PLUG_DETECT_AMP_ADJUST_HD 0x0       
				 TVE_COMPONENT_PLUG_DETECT_FRAME_COUNT 0x1F     
				 TVE_COMPONENT_PLUG_DETECT_VCOUNT 0x2          
				 TVE_COMPONENT_VDAC_ENBUF 0x0                  

				 >;
			table_1080p_25 = 
				</* field_index  field_value */
			 
				 TVE_COMPOSITE_Y_DELAY              0x0  
				 TVE_COMPOSITE_C_DELAY              0x2  
				 TVE_COMPOSITE_LUMA_LEVEL           0x50  
				 TVE_COMPOSITE_CHRMA_LEVEL          0x68  
				 TVE_COMPOSITE_SYNC_DELAY           0x0  
				 TVE_COMPOSITE_SYNC_LEVEL           0x4  
				 TVE_COMPOSITE_FILTER_C_ENALBE      0x0  
				 TVE_COMPOSITE_FILTER_Y_ENALBE      0x1  
				 TVE_COMPOSITE_PEDESTAL_LEVEL       0x0  
			
			
				 TVE_COMPONENT_IS_PAL               0x0  
				 TVE_COMPONENT_PAL_MODE             0x0  
				 TVE_COMPONENT_ALL_SMOOTH_ENABLE    0x0  
				 TVE_COMPONENT_BTB_ENALBE           0x0  
				 TVE_COMPONENT_INSERT0_ONOFF        0x1  
				 TVE_COMPONENT_DAC_UPSAMPLEN        0x1  
				 TVE_COMPONENT_Y_DELAY              0x6  
				 TVE_COMPONENT_CB_DELAY             0x5  
				 TVE_COMPONENT_CR_DELAY             0x5  
				 TVE_COMPONENT_LUM_LEVEL            0x52  
				 TVE_COMPONENT_CHRMA_LEVEL          0x52  
				 TVE_COMPONENT_PEDESTAL_LEVEL       0x0  
				 TVE_COMPONENT_UV_SYNC_ONOFF        0x0  
				 TVE_COMPONENT_SYNC_DELAY           0x5  
				 TVE_COMPONENT_SYNC_LEVEL           0x3  
				 TVE_COMPONENT_R_SYNC_ONOFF         0x0  
				 TVE_COMPONENT_G_SYNC_ONOFF         0x0  
				 TVE_COMPONENT_B_SYNC_ONOFF         0x0  
				 TVE_COMPONENT_RGB_R_LEVEL          0x49  
				 TVE_COMPONENT_RGB_G_LEVEL          0x49  
				 TVE_COMPONENT_RGB_B_LEVEL          0x49  
				 TVE_COMPONENT_FILTER_Y_ENALBE      0x1  
				 TVE_COMPONENT_FILTER_C_ENALBE      0x1  
				 TVE_COMPONENT_PEDESTAL_ONOFF       0x0  
				 TVE_COMPONENT_PED_RGB_YPBPR_ENABLE 0x0  
				 TVE_COMPONENT_PED_ADJUST           0x0  
				 TVE_COMPONENT_G2Y                  0x12a  
				 TVE_COMPONENT_G2U                  0x64  
				 TVE_COMPONENT_G2V                  0xd0  
				 TVE_COMPONENT_B2U                  0x21d  
				 TVE_COMPONENT_R2V                  0x1cb  
			
			
				 TVE_BURST_POS_ENABLE               0x0  
				 TVE_BURST_LEVEL_ENABLE             0x0  
				 TVE_BURST_CB_LEVEL                 0xd4  
				 TVE_BURST_CR_LEVEL                 0x0  
				 TVE_BURST_START_POS                0x0  
				 TVE_BURST_END_POS                  0x0  
				 TVE_BURST_SET_FREQ_MODE            0x0  
				 TVE_BURST_FREQ_SIGN                0x0  
				 TVE_BURST_PHASE_COMPENSATION       0x0  
				 TVE_BURST_FREQ_RESPONSE            0x0  
			
			
				 TVE_ASYNC_FIFO                     0x4  
				 TVE_CAV_SYNC_HIGH                  0x1  
				 TVE_SYNC_HIGH_WIDTH                0x6  
				 TVE_SYNC_LOW_WIDTH                 0xd  
			
			
				 TVE_VIDEO_DAC_FS                   0x0  
				 TVE_SECAM_PRE_COEFFA3A2            0x0  
				 TVE_SECAM_PRE_COEFFB1A4            0x0  
				 TVE_SECAM_PRE_COEFFB3B2            0x0  
				 TVE_SECAM_F0CB_CENTER              0x0  
				 TVE_SECAM_F0CR_CENTER              0x0  
				 TVE_SECAM_FM_KCBCR_AJUST           0x0  
				 TVE_SECAM_CONTROL                  0x0  
				 TVE_SECAM_NOTCH_COEFB1             0x0  
				 TVE_SECAM_NOTCH_COEFB2B3           0x0  
				 TVE_SECAM_NOTCH_COEFA2A3           0x0  
		     //added
		     TVE_COMPONENT_PLUG_OUT_EN          0x1  
				 TVE_COMPONENT_PLUG_DETECT_LINE_CNT_HD 0x6     
				 TVE_CB_CR_INSERT_SW                0x0  //0x84 28bit
				 TVE_VBI_LINE21_EN                  0x0  //0xc8 14bit
		     TVE_COMPONENT_PLUG_DETECT_AMP_ADJUST_HD                  0x60  
		     TVE_SCART_PLUG_DETECT_LINE_CNT_HD  0x0  
				 TVE_SCART_PLUG_DETECT_AMP_ADJUST_HD 0x0       

		     TVE_COMPONENT_PLUG_DETECT_FRAME_COUNT 0x1F  
		     TVE_COMPONENT_PLUG_DETECT_VCOUNT 0x2  
		     TVE_COMPONENT_VDAC_ENBUF 0x0  

   	>;
		table_1080p_30 =
		<  /* field_index  field_value */
	 
				 TVE_COMPOSITE_Y_DELAY              0x0  
				 TVE_COMPOSITE_C_DELAY              0x2  
				 TVE_COMPOSITE_LUMA_LEVEL           0x50  
				 TVE_COMPOSITE_CHRMA_LEVEL          0x68  
				 TVE_COMPOSITE_SYNC_DELAY           0x0  
				 TVE_COMPOSITE_SYNC_LEVEL           0x4  
				 TVE_COMPOSITE_FILTER_C_ENALBE      0x0  
				 TVE_COMPOSITE_FILTER_Y_ENALBE      0x1  
				 TVE_COMPOSITE_PEDESTAL_LEVEL       0x0  
			
			
				 TVE_COMPONENT_IS_PAL               0x0  
				 TVE_COMPONENT_PAL_MODE             0x0  
				 TVE_COMPONENT_ALL_SMOOTH_ENABLE    0x0  
				 TVE_COMPONENT_BTB_ENALBE           0x0  
				 TVE_COMPONENT_INSERT0_ONOFF        0x1  
				 TVE_COMPONENT_DAC_UPSAMPLEN        0x1  
				 TVE_COMPONENT_Y_DELAY              0x5  
				 TVE_COMPONENT_CB_DELAY             0x4  
				 TVE_COMPONENT_CR_DELAY             0x4  
				 TVE_COMPONENT_LUM_LEVEL            0x52  
				 TVE_COMPONENT_CHRMA_LEVEL          0x52  
				 TVE_COMPONENT_PEDESTAL_LEVEL       0x0  
				 TVE_COMPONENT_UV_SYNC_ONOFF        0x0  
				 TVE_COMPONENT_SYNC_DELAY           0x5  
				 TVE_COMPONENT_SYNC_LEVEL           0x3  
				 TVE_COMPONENT_R_SYNC_ONOFF         0x0  
				 TVE_COMPONENT_G_SYNC_ONOFF         0x0  
				 TVE_COMPONENT_B_SYNC_ONOFF         0x0  
				 TVE_COMPONENT_RGB_R_LEVEL          0x49  
				 TVE_COMPONENT_RGB_G_LEVEL          0x49  
				 TVE_COMPONENT_RGB_B_LEVEL          0x49  
				 TVE_COMPONENT_FILTER_Y_ENALBE      0x1  
				 TVE_COMPONENT_FILTER_C_ENALBE      0x1  
				 TVE_COMPONENT_PEDESTAL_ONOFF       0x0  
				 TVE_COMPONENT_PED_RGB_YPBPR_ENABLE 0x0  
				 TVE_COMPONENT_PED_ADJUST           0x0  
				 TVE_COMPONENT_G2Y                  0x12a  
				 TVE_COMPONENT_G2U                  0x64  
				 TVE_COMPONENT_G2V                  0xd0  
				 TVE_COMPONENT_B2U                  0x21d  
				 TVE_COMPONENT_R2V                  0x1cb  
			
			
				 TVE_BURST_POS_ENABLE               0x0  
				 TVE_BURST_LEVEL_ENABLE             0x0  
				 TVE_BURST_CB_LEVEL                 0xd4  
				 TVE_BURST_CR_LEVEL                 0x0  
				 TVE_BURST_START_POS                0x0  
				 TVE_BURST_END_POS                  0x0  
				 TVE_BURST_SET_FREQ_MODE            0x0  
				 TVE_BURST_FREQ_SIGN                0x0  
				 TVE_BURST_PHASE_COMPENSATION       0x0  
				 TVE_BURST_FREQ_RESPONSE            0x0  
			
			
				 TVE_ASYNC_FIFO                     0x4  
				 TVE_CAV_SYNC_HIGH                  0x1  
				 TVE_SYNC_HIGH_WIDTH                0x6  
				 TVE_SYNC_LOW_WIDTH                 0xd  
			
			
				 TVE_VIDEO_DAC_FS                   0x0  
				 TVE_SECAM_PRE_COEFFA3A2            0x0  
				 TVE_SECAM_PRE_COEFFB1A4            0x0  
				 TVE_SECAM_PRE_COEFFB3B2            0x0  
				 TVE_SECAM_F0CB_CENTER              0x0  
				 TVE_SECAM_F0CR_CENTER              0x0  
				 TVE_SECAM_FM_KCBCR_AJUST           0x0  
				 TVE_SECAM_CONTROL                  0x0  
				 TVE_SECAM_NOTCH_COEFB1             0x0  
				 TVE_SECAM_NOTCH_COEFB2B3           0x0  
				 TVE_SECAM_NOTCH_COEFA2A3           0x0  
				 TVE_COMPONENT_PLUG_OUT_EN          0x1        
				 TVE_COMPONENT_PLUG_DETECT_LINE_CNT_HD 0x6     
				 TVE_CB_CR_INSERT_SW                0x0        
				 TVE_VBI_LINE21_EN                  0x0        
				 TVE_COMPONENT_PLUG_DETECT_AMP_ADJUST_HD 0x60  
				 TVE_SCART_PLUG_DETECT_LINE_CNT_HD  0x0        
				 TVE_SCART_PLUG_DETECT_AMP_ADJUST_HD 0x0       
				 TVE_COMPONENT_PLUG_DETECT_FRAME_COUNT 0x1F     
				 TVE_COMPONENT_PLUG_DETECT_VCOUNT 0x2          
				 TVE_COMPONENT_VDAC_ENBUF 0x0                  
	>;
	table_1152i_25 = 
	< /* field_index  field_value */
		 
				 TVE_COMPOSITE_Y_DELAY              0x0  
				 TVE_COMPOSITE_C_DELAY              0x2  
				 TVE_COMPOSITE_LUMA_LEVEL           0x50  
				 TVE_COMPOSITE_CHRMA_LEVEL          0x68  
				 TVE_COMPOSITE_SYNC_DELAY           0x0  
				 TVE_COMPOSITE_SYNC_LEVEL           0x4  
				 TVE_COMPOSITE_FILTER_C_ENALBE      0x0  
				 TVE_COMPOSITE_FILTER_Y_ENALBE      0x1  
				 TVE_COMPOSITE_PEDESTAL_LEVEL       0x0  
			
			
				 TVE_COMPONENT_IS_PAL               0x0  
				 TVE_COMPONENT_PAL_MODE             0x0  
				 TVE_COMPONENT_ALL_SMOOTH_ENABLE    0x0  
				 TVE_COMPONENT_BTB_ENALBE           0x0  
				 TVE_COMPONENT_INSERT0_ONOFF        0x1  
				 TVE_COMPONENT_DAC_UPSAMPLEN        0x1  
				 TVE_COMPONENT_Y_DELAY              0x6  
				 TVE_COMPONENT_CB_DELAY             0x5  
				 TVE_COMPONENT_CR_DELAY             0x5  
				 TVE_COMPONENT_LUM_LEVEL            0x52  
				 TVE_COMPONENT_CHRMA_LEVEL          0x4d  
				 TVE_COMPONENT_PEDESTAL_LEVEL       0x0  
				 TVE_COMPONENT_UV_SYNC_ONOFF        0x0  
				 TVE_COMPONENT_SYNC_DELAY           0x5  
				 TVE_COMPONENT_SYNC_LEVEL           0x3  
				 TVE_COMPONENT_R_SYNC_ONOFF         0x0  
				 TVE_COMPONENT_G_SYNC_ONOFF         0x0  
				 TVE_COMPONENT_B_SYNC_ONOFF         0x0  
				 TVE_COMPONENT_RGB_R_LEVEL          0x49  
				 TVE_COMPONENT_RGB_G_LEVEL          0x49  
				 TVE_COMPONENT_RGB_B_LEVEL          0x49  
				 TVE_COMPONENT_FILTER_Y_ENALBE      0x1  
				 TVE_COMPONENT_FILTER_C_ENALBE      0x1  
				 TVE_COMPONENT_PEDESTAL_ONOFF       0x0  
				 TVE_COMPONENT_PED_RGB_YPBPR_ENABLE 0x0  
				 TVE_COMPONENT_PED_ADJUST           0x0  
				 TVE_COMPONENT_G2Y                  0x12a  
				 TVE_COMPONENT_G2U                  0x64  
				 TVE_COMPONENT_G2V                  0xd0  
				 TVE_COMPONENT_B2U                  0x21d  
				 TVE_COMPONENT_R2V                  0x1cb  
			
			
				 TVE_BURST_POS_ENABLE               0x0  
				 TVE_BURST_LEVEL_ENABLE             0x0  
				 TVE_BURST_CB_LEVEL                 0xd4  
				 TVE_BURST_CR_LEVEL                 0x0  
				 TVE_BURST_START_POS                0x0  
				 TVE_BURST_END_POS                  0x0  
				 TVE_BURST_SET_FREQ_MODE            0x0  
				 TVE_BURST_FREQ_SIGN                0x0  
				 TVE_BURST_PHASE_COMPENSATION       0x0  
				 TVE_BURST_FREQ_RESPONSE            0x0  
			
			
				 TVE_ASYNC_FIFO                     0x4  
				 TVE_CAV_SYNC_HIGH                  0x1  
				 TVE_SYNC_HIGH_WIDTH                0x6  
				 TVE_SYNC_LOW_WIDTH                 0xd  
			
			
				 TVE_VIDEO_DAC_FS                   0x0  
				 TVE_SECAM_PRE_COEFFA3A2            0x0  
				 TVE_SECAM_PRE_COEFFB1A4            0x0  
				 TVE_SECAM_PRE_COEFFB3B2            0x0  
				 TVE_SECAM_F0CB_CENTER              0x0  
				 TVE_SECAM_F0CR_CENTER              0x0  
				 TVE_SECAM_FM_KCBCR_AJUST           0x0  
				 TVE_SECAM_CONTROL                  0x0  
				 TVE_SECAM_NOTCH_COEFB1             0x0  
				 TVE_SECAM_NOTCH_COEFB2B3           0x0  
				 TVE_SECAM_NOTCH_COEFA2A3           0x0  
				 TVE_COMPONENT_PLUG_OUT_EN          0x1        
				 TVE_COMPONENT_PLUG_DETECT_LINE_CNT_HD 0x6     
				 TVE_CB_CR_INSERT_SW                0x0        
				 TVE_VBI_LINE21_EN                  0x0        
				 TVE_COMPONENT_PLUG_DETECT_AMP_ADJUST_HD 0x60  
				 TVE_SCART_PLUG_DETECT_LINE_CNT_HD  0x0        
				 TVE_SCART_PLUG_DETECT_AMP_ADJUST_HD 0x0       
				 TVE_COMPONENT_PLUG_DETECT_FRAME_COUNT 0x1F     
				 TVE_COMPONENT_PLUG_DETECT_VCOUNT 0x2          
				 TVE_COMPONENT_VDAC_ENBUF 0x0                  

				>;
			table_1080IASS = 
				< /* field_index  field_value */
		 
				 TVE_COMPOSITE_Y_DELAY              0x0  
				 TVE_COMPOSITE_C_DELAY              0x2  
				 TVE_COMPOSITE_LUMA_LEVEL           0x50  
				 TVE_COMPOSITE_CHRMA_LEVEL          0x68  
				 TVE_COMPOSITE_SYNC_DELAY           0x0  
				 TVE_COMPOSITE_SYNC_LEVEL           0x4  
				 TVE_COMPOSITE_FILTER_C_ENALBE      0x0  
				 TVE_COMPOSITE_FILTER_Y_ENALBE      0x1  
				 TVE_COMPOSITE_PEDESTAL_LEVEL       0x0  
			
			
				 TVE_COMPONENT_IS_PAL               0x0  
				 TVE_COMPONENT_PAL_MODE             0x0  
				 TVE_COMPONENT_ALL_SMOOTH_ENABLE    0x0  
				 TVE_COMPONENT_BTB_ENALBE           0x0  
				 TVE_COMPONENT_INSERT0_ONOFF        0x1  
				 TVE_COMPONENT_DAC_UPSAMPLEN        0x1  
				 TVE_COMPONENT_Y_DELAY              0x6  
				 TVE_COMPONENT_CB_DELAY             0x5  
				 TVE_COMPONENT_CR_DELAY             0x5  
				 TVE_COMPONENT_LUM_LEVEL            0x52  
				 TVE_COMPONENT_CHRMA_LEVEL          0x4d  
				 TVE_COMPONENT_PEDESTAL_LEVEL       0x0  
				 TVE_COMPONENT_UV_SYNC_ONOFF        0x0  
				 TVE_COMPONENT_SYNC_DELAY           0x5  
				 TVE_COMPONENT_SYNC_LEVEL           0x3  
				 TVE_COMPONENT_R_SYNC_ONOFF         0x0  
				 TVE_COMPONENT_G_SYNC_ONOFF         0x0  
				 TVE_COMPONENT_B_SYNC_ONOFF         0x0  
				 TVE_COMPONENT_RGB_R_LEVEL          0x49  
				 TVE_COMPONENT_RGB_G_LEVEL          0x49  
				 TVE_COMPONENT_RGB_B_LEVEL          0x49  
				 TVE_COMPONENT_FILTER_Y_ENALBE      0x1  
				 TVE_COMPONENT_FILTER_C_ENALBE      0x1  
				 TVE_COMPONENT_PEDESTAL_ONOFF       0x0  
				 TVE_COMPONENT_PED_RGB_YPBPR_ENABLE 0x0  
				 TVE_COMPONENT_PED_ADJUST           0x0  
				 TVE_COMPONENT_G2Y                  0x12a  
				 TVE_COMPONENT_G2U                  0x64  
				 TVE_COMPONENT_G2V                  0xd0  
				 TVE_COMPONENT_B2U                  0x21d  
				 TVE_COMPONENT_R2V                  0x1cb  
			
			
				 TVE_BURST_POS_ENABLE               0x0  
				 TVE_BURST_LEVEL_ENABLE             0x0  
				 TVE_BURST_CB_LEVEL                 0xd4  
				 TVE_BURST_CR_LEVEL                 0x0  
				 TVE_BURST_START_POS                0x0  
				 TVE_BURST_END_POS                  0x0  
				 TVE_BURST_SET_FREQ_MODE            0x0  
				 TVE_BURST_FREQ_SIGN                0x0  
				 TVE_BURST_PHASE_COMPENSATION       0x0  
				 TVE_BURST_FREQ_RESPONSE            0x0  
			
			
				 TVE_ASYNC_FIFO                     0x4  
				 TVE_CAV_SYNC_HIGH                  0x1  
				 TVE_SYNC_HIGH_WIDTH                0x6  
				 TVE_SYNC_LOW_WIDTH                 0xd  
			
			
				 TVE_VIDEO_DAC_FS                   0x0  
				 TVE_SECAM_PRE_COEFFA3A2            0x0  
				 TVE_SECAM_PRE_COEFFB1A4            0x0  
				 TVE_SECAM_PRE_COEFFB3B2            0x0  
				 TVE_SECAM_F0CB_CENTER              0x0  
				 TVE_SECAM_F0CR_CENTER              0x0  
				 TVE_SECAM_FM_KCBCR_AJUST           0x0  
				 TVE_SECAM_CONTROL                  0x0  
				 TVE_SECAM_NOTCH_COEFB1             0x0  
				 TVE_SECAM_NOTCH_COEFB2B3           0x0  
				 TVE_SECAM_NOTCH_COEFA2A3           0x0  
				 TVE_COMPONENT_PLUG_OUT_EN          0x1        
				 TVE_COMPONENT_PLUG_DETECT_LINE_CNT_HD 0x6     
				 TVE_CB_CR_INSERT_SW                0x0        
				 TVE_VBI_LINE21_EN                  0x0        
				 TVE_COMPONENT_PLUG_DETECT_AMP_ADJUST_HD 0x60  
				 TVE_SCART_PLUG_DETECT_LINE_CNT_HD  0x0        
				 TVE_SCART_PLUG_DETECT_AMP_ADJUST_HD 0x0       
				 TVE_COMPONENT_PLUG_DETECT_FRAME_COUNT 0x1F     
				 TVE_COMPONENT_PLUG_DETECT_VCOUNT 0x2          
				 TVE_COMPONENT_VDAC_ENBUF 0x0                  

	>;
	table_1080p_50 = 
	< /* field_index  field_value */
		 
				 TVE_COMPOSITE_Y_DELAY              0x0  
				 TVE_COMPOSITE_C_DELAY              0x2  
				 TVE_COMPOSITE_LUMA_LEVEL           0x50  
				 TVE_COMPOSITE_CHRMA_LEVEL          0x68  
				 TVE_COMPOSITE_SYNC_DELAY           0x0  
				 TVE_COMPOSITE_SYNC_LEVEL           0x4  
				 TVE_COMPOSITE_FILTER_C_ENALBE      0x0  
				 TVE_COMPOSITE_FILTER_Y_ENALBE      0x1  
				 TVE_COMPOSITE_PEDESTAL_LEVEL       0x0  
			
			
				 TVE_COMPONENT_IS_PAL               0x0  
				 TVE_COMPONENT_PAL_MODE             0x0  
				 TVE_COMPONENT_ALL_SMOOTH_ENABLE    0x0  
				 TVE_COMPONENT_BTB_ENALBE           0x0  
				 TVE_COMPONENT_INSERT0_ONOFF        0x1  
				 TVE_COMPONENT_DAC_UPSAMPLEN        0x1  
				 TVE_COMPONENT_Y_DELAY              0x6  
				 TVE_COMPONENT_CB_DELAY             0x6  
				 TVE_COMPONENT_CR_DELAY             0x6  
				 TVE_COMPONENT_LUM_LEVEL            0x52  
				 TVE_COMPONENT_CHRMA_LEVEL          0x51  
				 TVE_COMPONENT_PEDESTAL_LEVEL       0x0  
				 TVE_COMPONENT_UV_SYNC_ONOFF        0x0  
				 TVE_COMPONENT_SYNC_DELAY           0x0  
				 TVE_COMPONENT_SYNC_LEVEL           0x3  
				 TVE_COMPONENT_R_SYNC_ONOFF         0x0  
				 TVE_COMPONENT_G_SYNC_ONOFF         0x0  
				 TVE_COMPONENT_B_SYNC_ONOFF         0x0  
				 TVE_COMPONENT_RGB_R_LEVEL          0x49  
				 TVE_COMPONENT_RGB_G_LEVEL          0x49  
				 TVE_COMPONENT_RGB_B_LEVEL          0x49  
				 TVE_COMPONENT_FILTER_Y_ENALBE      0x1  
				 TVE_COMPONENT_FILTER_C_ENALBE      0x1  
				 TVE_COMPONENT_PEDESTAL_ONOFF       0x0  
				 TVE_COMPONENT_PED_RGB_YPBPR_ENABLE 0x0  
				 TVE_COMPONENT_PED_ADJUST           0x0  
				 TVE_COMPONENT_G2Y                  0x12a  
				 TVE_COMPONENT_G2U                  0x64  
				 TVE_COMPONENT_G2V                  0xd0  
				 TVE_COMPONENT_B2U                  0x21d  
				 TVE_COMPONENT_R2V                  0x1cb  
			
			
				 TVE_BURST_POS_ENABLE               0x0  
				 TVE_BURST_LEVEL_ENABLE             0x0  
				 TVE_BURST_CB_LEVEL                 0xd4  
				 TVE_BURST_CR_LEVEL                 0x0  
				 TVE_BURST_START_POS                0x0  
				 TVE_BURST_END_POS                  0x0  
				 TVE_BURST_SET_FREQ_MODE            0x0  
				 TVE_BURST_FREQ_SIGN                0x0  
				 TVE_BURST_PHASE_COMPENSATION       0x0  
				 TVE_BURST_FREQ_RESPONSE            0x0  
			
			
				 TVE_ASYNC_FIFO                     0x2  
				 TVE_CAV_SYNC_HIGH                  0x2  
				 TVE_SYNC_HIGH_WIDTH                0x0  
				 TVE_SYNC_LOW_WIDTH                 0xd  
			
			
				 TVE_VIDEO_DAC_FS                   0x0  
				 TVE_SECAM_PRE_COEFFA3A2            0x0  
				 TVE_SECAM_PRE_COEFFB1A4            0x0  
				 TVE_SECAM_PRE_COEFFB3B2            0x0  
				 TVE_SECAM_F0CB_CENTER              0x0  
				 TVE_SECAM_F0CR_CENTER              0x0  
				 TVE_SECAM_FM_KCBCR_AJUST           0x0  
				 TVE_SECAM_CONTROL                  0x0  
				 TVE_SECAM_NOTCH_COEFB1             0x0  
				 TVE_SECAM_NOTCH_COEFB2B3           0x0  
				 TVE_SECAM_NOTCH_COEFA2A3           0x0  
			    //added
			   TVE_COMPONENT_PLUG_OUT_EN          0x1  
				 TVE_COMPONENT_PLUG_DETECT_LINE_CNT_HD 0x6     
				 TVE_CB_CR_INSERT_SW                0x1  //0x84 28bit
				 TVE_VBI_LINE21_EN                  0x0  //0xc8 14bit
			   TVE_COMPONENT_PLUG_DETECT_AMP_ADJUST_HD                  0x60  
			   TVE_SCART_PLUG_DETECT_LINE_CNT_HD  0x0  
				 TVE_SCART_PLUG_DETECT_AMP_ADJUST_HD 0x0       
			
		
		     TVE_COMPONENT_PLUG_DETECT_FRAME_COUNT 0x1F  
		     TVE_COMPONENT_PLUG_DETECT_VCOUNT 0x2  
		     TVE_COMPONENT_VDAC_ENBUF 0x0  
	>;
	table_1080p_60 = 
	< /* field_index  field_value */				 
						  
				 TVE_COMPOSITE_Y_DELAY              0x0  
				 TVE_COMPOSITE_C_DELAY              0x2  
				 TVE_COMPOSITE_LUMA_LEVEL           0x50  
				 TVE_COMPOSITE_CHRMA_LEVEL          0x68  
				 TVE_COMPOSITE_SYNC_DELAY           0x0  
				 TVE_COMPOSITE_SYNC_LEVEL           0x4  
				 TVE_COMPOSITE_FILTER_C_ENALBE      0x0  
				 TVE_COMPOSITE_FILTER_Y_ENALBE      0x1  
				 TVE_COMPOSITE_PEDESTAL_LEVEL       0x0  
			
			
				 TVE_COMPONENT_IS_PAL               0x0  
				 TVE_COMPONENT_PAL_MODE             0x0  
				 TVE_COMPONENT_ALL_SMOOTH_ENABLE    0x0  
				 TVE_COMPONENT_BTB_ENALBE           0x0  
				 TVE_COMPONENT_INSERT0_ONOFF        0x1  
				 TVE_COMPONENT_DAC_UPSAMPLEN        0x1  
				 TVE_COMPONENT_Y_DELAY              0x4  
				 TVE_COMPONENT_CB_DELAY             0x5  
				 TVE_COMPONENT_CR_DELAY             0x5  
				 TVE_COMPONENT_LUM_LEVEL            0x52  
				 TVE_COMPONENT_CHRMA_LEVEL          0x51  
				 TVE_COMPONENT_PEDESTAL_LEVEL       0x0  
				 TVE_COMPONENT_UV_SYNC_ONOFF        0x0  
				 TVE_COMPONENT_SYNC_DELAY           0x0  
				 TVE_COMPONENT_SYNC_LEVEL           0x3  
				 TVE_COMPONENT_R_SYNC_ONOFF         0x0  
				 TVE_COMPONENT_G_SYNC_ONOFF         0x0  
				 TVE_COMPONENT_B_SYNC_ONOFF         0x0  
				 TVE_COMPONENT_RGB_R_LEVEL          0x49  
				 TVE_COMPONENT_RGB_G_LEVEL          0x49  
				 TVE_COMPONENT_RGB_B_LEVEL          0x49  
				 TVE_COMPONENT_FILTER_Y_ENALBE      0x1  
				 TVE_COMPONENT_FILTER_C_ENALBE      0x1  
				 TVE_COMPONENT_PEDESTAL_ONOFF       0x0  
				 TVE_COMPONENT_PED_RGB_YPBPR_ENABLE 0x0  
				 TVE_COMPONENT_PED_ADJUST           0x0  
				 TVE_COMPONENT_G2Y                  0x12a  
				 TVE_COMPONENT_G2U                  0x64  
				 TVE_COMPONENT_G2V                  0xd0  
				 TVE_COMPONENT_B2U                  0x21d  
				 TVE_COMPONENT_R2V                  0x1cb  
			
			
				 TVE_BURST_POS_ENABLE               0x0  
				 TVE_BURST_LEVEL_ENABLE             0x0  
				 TVE_BURST_CB_LEVEL                 0xd4  
				 TVE_BURST_CR_LEVEL                 0x0  
				 TVE_BURST_START_POS                0x0  
				 TVE_BURST_END_POS                  0x0  
				 TVE_BURST_SET_FREQ_MODE            0x0  
				 TVE_BURST_FREQ_SIGN                0x0  
				 TVE_BURST_PHASE_COMPENSATION       0x0  
				 TVE_BURST_FREQ_RESPONSE            0x0  
			
			
				 TVE_ASYNC_FIFO                     0x2  
				 TVE_CAV_SYNC_HIGH                  0x2  
				 TVE_SYNC_HIGH_WIDTH                0xb  
				 TVE_SYNC_LOW_WIDTH                 0xb  
			
			
				 TVE_VIDEO_DAC_FS                   0x0  
				 TVE_SECAM_PRE_COEFFA3A2            0x0  
				 TVE_SECAM_PRE_COEFFB1A4            0x0  
				 TVE_SECAM_PRE_COEFFB3B2            0x0  
				 TVE_SECAM_F0CB_CENTER              0x0  
				 TVE_SECAM_F0CR_CENTER              0x0  
				 TVE_SECAM_FM_KCBCR_AJUST           0x0  
				 TVE_SECAM_CONTROL                  0x0  
				 TVE_SECAM_NOTCH_COEFB1             0x0  
				 TVE_SECAM_NOTCH_COEFB2B3           0x0  
				 TVE_SECAM_NOTCH_COEFA2A3           0x0  
		     //added
		     TVE_COMPONENT_PLUG_OUT_EN          0x1  
				 TVE_COMPONENT_PLUG_DETECT_LINE_CNT_HD 0x6     
				 TVE_CB_CR_INSERT_SW                0x1  //0x84 28bit
				 TVE_VBI_LINE21_EN                  0x0  //0xc8 14bit
		     TVE_COMPONENT_PLUG_DETECT_AMP_ADJUST_HD                  0x60  
		     TVE_SCART_PLUG_DETECT_LINE_CNT_HD  0x0  
				 TVE_SCART_PLUG_DETECT_AMP_ADJUST_HD 0x0       

		     TVE_COMPONENT_PLUG_DETECT_FRAME_COUNT 0x1F  
		     TVE_COMPONENT_PLUG_DETECT_VCOUNT 0x2  
		     TVE_COMPONENT_VDAC_ENBUF 0x0  

		>;
		tve_adjust_table =
				"table_576i",
       	"table_480i",
        "table_576p",
        "table_480p",
        "table_720p_50",
        "table_720p_60",
       	"table_1080i_25",
        "table_1080i_30",
        "table_1080p_24",
        "table_1080p_25",
        "table_1080p_30",
        "table_1152i_25",
        "table_1080IASS",
        "table_1080p_50",
        "table_1080p_60";

		sd_tve_adj_table_info = 
												 </* type  sys  value */ 
			 
										     TVE_ADJ_COMPOSITE_Y_DELAY  SYS_625_LINE  1   
										     TVE_ADJ_COMPOSITE_Y_DELAY  SYS_525_LINE  1  
										     TVE_ADJ_COMPOSITE_C_DELAY  SYS_625_LINE  0   
										     TVE_ADJ_COMPOSITE_C_DELAY  SYS_525_LINE  0  
										     TVE_ADJ_COMPONENT_Y_DELAY  SYS_625_LINE  4   
										     TVE_ADJ_COMPONENT_Y_DELAY  SYS_525_LINE  4  
										     TVE_ADJ_COMPONENT_CB_DELAY  SYS_625_LINE  3   
										     TVE_ADJ_COMPONENT_CB_DELAY  SYS_525_LINE  3  
										     TVE_ADJ_COMPONENT_CR_DELAY  SYS_625_LINE  1   
										     TVE_ADJ_COMPONENT_CR_DELAY  SYS_525_LINE  1  
										     TVE_ADJ_BURST_LEVEL_ENABLE  SYS_625_LINE  1   
										     TVE_ADJ_BURST_LEVEL_ENABLE  SYS_525_LINE  0  
										     TVE_ADJ_BURST_CB_LEVEL  SYS_625_LINE  CB_LEVEL_PAL_SD/**/   
										     TVE_ADJ_BURST_CB_LEVEL  SYS_525_LINE  CB_LEVEL_NTSC_SD/**/  
										     TVE_ADJ_BURST_CR_LEVEL  SYS_625_LINE  CR_LEVEL_PAL_SD/**/   
										     TVE_ADJ_BURST_CR_LEVEL  SYS_525_LINE  CR_LEVEL_NTSC_SD/**/  
										     TVE_ADJ_COMPOSITE_LUMA_LEVEL  SYS_625_LINE  LUMA_LEVEL_PAL_SD/**/   
										     TVE_ADJ_COMPOSITE_LUMA_LEVEL  SYS_525_LINE  LUMA_LEVEL_NTSC_SD/**/  
										     TVE_ADJ_COMPOSITE_CHRMA_LEVEL  SYS_625_LINE  CHRMA_LEVEL_PAL_SD/**/   
										     TVE_ADJ_COMPOSITE_CHRMA_LEVEL  SYS_525_LINE  CHRMA_LEVEL_NTSC_SD/**/  
										     TVE_ADJ_PHASE_COMPENSATION  SYS_625_LINE  0x280    TVE_ADJ_PHASE_COMPENSATION  SYS_525_LINE  0x04a0  
										     TVE_ADJ_VIDEO_FREQ_RESPONSE  SYS_625_LINE  FREQ_RESPONSE_PAL_SD/**/   
										     TVE_ADJ_VIDEO_FREQ_RESPONSE  SYS_525_LINE  FREQ_RESPONSE_NTSC_SD/**/  
										 
													>;

		sd_tve_adv_adj_table_info =
												< /* type  sys  value */ 
											 
									     TVE_ADJ_ADV_PEDESTAL_ONOFF  SYS_625_LINE  0                
									     TVE_ADJ_ADV_PEDESTAL_ONOFF  SYS_525_LINE  1  
									     TVE_ADJ_ADV_COMPONENT_LUM_LEVEL  SYS_625_LINE  0x53        
									     TVE_ADJ_ADV_COMPONENT_LUM_LEVEL  SYS_525_LINE  0x4f  
									     TVE_ADJ_ADV_COMPONENT_CHRMA_LEVEL  SYS_625_LINE  0x51      
									     TVE_ADJ_ADV_COMPONENT_CHRMA_LEVEL  SYS_525_LINE  0x51  
									     TVE_ADJ_ADV_COMPONENT_PEDESTAL_LEVEL  SYS_625_LINE  0x0    
									     TVE_ADJ_ADV_COMPONENT_PEDESTAL_LEVEL  SYS_525_LINE  0x9  
									     TVE_ADJ_ADV_COMPONENT_SYNC_LEVEL  SYS_625_LINE  0x0        
									     TVE_ADJ_ADV_COMPONENT_SYNC_LEVEL  SYS_525_LINE  0x4  
									     TVE_ADJ_ADV_RGB_R_LEVEL  SYS_625_LINE  0x8f                
									     TVE_ADJ_ADV_RGB_R_LEVEL  SYS_525_LINE  0x92  
									     TVE_ADJ_ADV_RGB_G_LEVEL  SYS_625_LINE  0x8e                
									     TVE_ADJ_ADV_RGB_G_LEVEL  SYS_525_LINE  0x91  
									     TVE_ADJ_ADV_RGB_B_LEVEL  SYS_625_LINE  0x8e                
									     TVE_ADJ_ADV_RGB_B_LEVEL  SYS_525_LINE  0x91  
									     TVE_ADJ_ADV_COMPOSITE_PEDESTAL_LEVEL  SYS_625_LINE  0x0    
									     TVE_ADJ_ADV_COMPOSITE_PEDESTAL_LEVEL  SYS_525_LINE  0x2b  
									     TVE_ADJ_ADV_COMPOSITE_SYNC_LEVEL  SYS_625_LINE  0x0        
									     TVE_ADJ_ADV_COMPOSITE_SYNC_LEVEL  SYS_525_LINE  0x5  
									     TVE_ADJ_ADV_PLUG_OUT_EN  SYS_625_LINE  0x0                 
									     TVE_ADJ_ADV_PLUG_OUT_EN  SYS_525_LINE  0x0  
									     TVE_ADJ_ADV_PLUG_DETECT_LINE_CNT_SD  SYS_625_LINE  0x0        
									     TVE_ADJ_ADV_PLUG_DETECT_LINE_CNT_SD  SYS_525_LINE  0x0  
									     TVE_ADJ_ADV_PLUG_DETECT_AMP_ADJUST_SD  SYS_625_LINE  0x0      
									     TVE_ADJ_ADV_PLUG_DETECT_AMP_ADJUST_SD  SYS_525_LINE  0x0  
											  >;
		};
		boot_media_info{
			compatible="alitech,boot_media_info";
			play_enable = <0x1>;
			start_cmd		= <0x0>;
			finish_cmd	= <0x0>;
			jpeg_show_status	= <0x0>;	
			mpeg2_show_status	= <0x0>;
			mkv_show_status	= <0x0>;
			smart_output_enable	= <0x0>;
		};
		gma_info{
             compatible="alitech,gma_info";
             gma_enable = <0x0>;
             gma_layer_id = <0x0>;
             format = <0x0>;
             x = <0x0>;
             y = <0x0>;
             w = <0x0>;
             h = <0x0>;
             gma_buffer = <0x0>;
             gma_pitch = <0x0>;
     				 pallett = <
                         0x0 0x0 0x0 0x0 0x0 0x0 0x0 0x0 0x0 0x0 0x0 0x0 0x0 0x0 0x0 0x0 0x0 0x0 0x0 0x0
                         0x0 0x0 0x0 0x0 0x0 0x0 0x0 0x0 0x0 0x0 0x0 0x0 0x0 0x0 0x0 0x0 0x0 0x0 0x0 0x0
                         0x0 0x0 0x0 0x0 0x0 0x0 0x0 0x0 0x0 0x0 0x0 0x0 0x0 0x0 0x0 0x0 0x0 0x0 0x0 0x0
                         0x0 0x0 0x0 0x0 0x0 0x0 0x0 0x0 0x0 0x0 0x0 0x0 0x0 0x0 0x0 0x0 0x0 0x0 0x0 0x0
                         0x0 0x0 0x0 0x0 0x0 0x0 0x0 0x0 0x0 0x0 0x0 0x0 0x0 0x0 0x0 0x0 0x0 0x0 0x0 0x0
                         0x0 0x0 0x0 0x0 0x0 0x0 0x0 0x0 0x0 0x0 0x0 0x0 0x0 0x0 0x0 0x0 0x0 0x0 0x0 0x0
                         0x0 0x0 0x0 0x0 0x0 0x0 0x0 0x0 0x0 0x0 0x0 0x0 0x0 0x0 0x0 0x0 0x0 0x0 0x0 0x0
                         0x0 0x0 0x0 0x0 0x0 0x0 0x0 0x0 0x0 0x0 0x0 0x0 0x0 0x0 0x0 0x0 0x0 0x0 0x0 0x0
                         0x0 0x0 0x0 0x0 0x0 0x0 0x0 0x0 0x0 0x0 0x0 0x0 0x0 0x0 0x0 0x0 0x0 0x0 0x0 0x0
                         0x0 0x0 0x0 0x0 0x0 0x0 0x0 0x0 0x0 0x0 0x0 0x0 0x0 0x0 0x0 0x0 0x0 0x0 0x0 0x0
                         0x0 0x0 0x0 0x0 0x0 0x0 0x0 0x0 0x0 0x0 0x0 0x0 0x0 0x0 0x0 0x0 0x0 0x0 0x0 0x0
                         0x0 0x0 0x0 0x0 0x0 0x0 0x0 0x0 0x0 0x0 0x0 0x0 0x0 0x0 0x0 0x0 0x0 0x0 0x0 0x0
                         0x0 0x0 0x0 0x0 0x0 0x0 0x0 0x0 0x0 0x0 0x0 0x0 0x0 0x0 0x0 0x0 
                       >;
            full_screen = <0x0>;
     };
};
